# CY8C3246PVI_147 register map
File version: 0.1
CY8C32
Registers are 8-bit, read-write, no defined reset value unless marked. A register's access mark holds for its fields unless they carry their own. Offsets are from the block's base; lines under a group give offsets from that group; [hi:lo] are bit positions; {n}, {i} and the like mark numbered series; 'fields as' and 'values as' point back to an identical list; <NAME> marks a mode.

## Memory map
0x00000000 UART_RS485 — UART
0x00000000 ADC
0x00000000 MY_TIMER
0x00000000 COUNTER_ENC
0x00000000 WATCHDOG_COUNTER
0x00000000 PWM_MOTORS
0x00000000 PACER_TIMER
0x00006460 FF_STATUS
0x00006471 RESET_FF
0x00006472 RS485_CTS
0x00006473 FTDI_ENABLE_REG
0x00006474 WATCHDOG_REFRESH
0x00006477 WATCHDOG_ENABLER
0x00006478 MOTOR_ON_OFF
0x00006564 ADC_STATUS
0x00006574 POWER_ON_LED_REG
0x00006576 ADC_SOC
0x00006577 MOTOR_DIR
0x0000657B RESET_COUNTERS

## UART_RS485 — UART
Base 0x00000000
0x642B RX_UART_RS485_RX_ADDRESS1 — RX Address1 Register
0x643B RX_UART_RS485_RX_ADDRESS2 — RX Address2 Register
0x6443 TX_UART_RS485_TX_DATA — TX Data Register
0x644B RX_UART_RS485_RX_DATA — RX Data Register
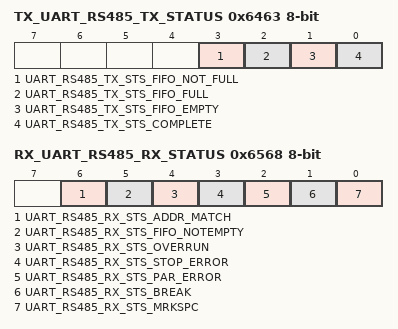
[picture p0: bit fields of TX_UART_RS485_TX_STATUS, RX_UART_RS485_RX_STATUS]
0x6463 TX_UART_RS485_TX_STATUS — TX status register
  [3] UART_RS485_TX_STS_FIFO_NOT_FULL ro, [2] UART_RS485_TX_STS_FIFO_FULL ro, [1] UART_RS485_TX_STS_FIFO_EMPTY ro, [0] UART_RS485_TX_STS_COMPLETE ro
0x6568 RX_UART_RS485_RX_STATUS — RX status register
  [6] UART_RS485_RX_STS_ADDR_MATCH ro, [5] UART_RS485_RX_STS_FIFO_NOTEMPTY ro, [4] UART_RS485_RX_STS_OVERRUN ro, [3] UART_RS485_RX_STS_STOP_ERROR ro, [2] UART_RS485_RX_STS_PAR_ERROR ro, [1] UART_RS485_RX_STS_BREAK ro, [0] UART_RS485_RX_STS_MRKSPC ro

## ADC_STATUS
Base 0x00006564
0x00 ADC_STATUS_STATUS_REG
0x20 ADC_STATUS_MASK_REG
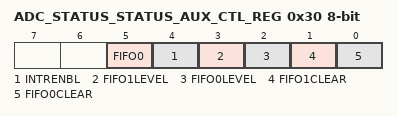
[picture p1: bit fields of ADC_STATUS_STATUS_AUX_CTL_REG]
0x30 ADC_STATUS_STATUS_AUX_CTL_REG
  [5] FIFO0 — FIFO0 clear
    1=ENABLED (Enable counter); 0=DISABLED (Disable counter)
  [4] INTRENBL — Enables or disables the Interrupt
    1=ENABLED (Interrupt enabled); 0=DISABLED (Interrupt disabled)
  [3] FIFO1LEVEL — FIFO level
    1=ENABLED (FIFO LVL: input mode: FIFO at least 1/2 empty; output mode: FIFO at least 1/2 full); 0=DISABLED (FIFO LVL: input mode: FIFO not full; output mode: FIFO not empty)
  [2] FIFO0LEVEL — FIFO level
    values as FIFO1LEVEL
  [1] FIFO1CLEAR — FIFO clear
    1=ENABLED (Clear FIFO state); 0=DISABLED (Normal FIFO operation)
  [0] FIFO0CLEAR — FIFO clear
    values as FIFO1CLEAR

## FF_STATUS
Base 0x00006460
Registers as ADC_STATUS (with ADC_STATUS read as FF_STATUS).

## MOTOR_ON_OFF
Base 0x00006478
0x00 MOTOR_ON_OFF_CONTROL_REG

## FTDI_ENABLE_REG
Base 0x00006473
Registers as MOTOR_ON_OFF (with MOTOR_ON_OFF read as FTDI_ENABLE_REG).

## RS485_CTS
Base 0x00006472
Registers as MOTOR_ON_OFF (with MOTOR_ON_OFF read as RS485_CTS).

## POWER_ON_LED_REG
Base 0x00006574
Registers as MOTOR_ON_OFF (with MOTOR_ON_OFF read as POWER_ON_LED_REG).

## ADC_SOC
Base 0x00006576
Registers as MOTOR_ON_OFF (with MOTOR_ON_OFF read as ADC_SOC).

## MOTOR_DIR
Base 0x00006577
Registers as MOTOR_ON_OFF (with MOTOR_ON_OFF read as MOTOR_DIR).

## RESET_COUNTERS
Base 0x0000657B
Registers as MOTOR_ON_OFF (with MOTOR_ON_OFF read as RESET_COUNTERS).

## WATCHDOG_ENABLER
Base 0x00006477
Registers as MOTOR_ON_OFF (with MOTOR_ON_OFF read as WATCHDOG_ENABLER).

## WATCHDOG_REFRESH
Base 0x00006474
Registers as MOTOR_ON_OFF (with MOTOR_ON_OFF read as WATCHDOG_REFRESH).

## RESET_FF
Base 0x00006471
Registers as MOTOR_ON_OFF (with MOTOR_ON_OFF read as RESET_FF).

## MY_TIMER
Base 0x00000000
0x43A3 MY_TIMER_GLOBAL_ENABLE — PM.ACT.CFG
  [3:0] en_timer — Enable timer/counters.
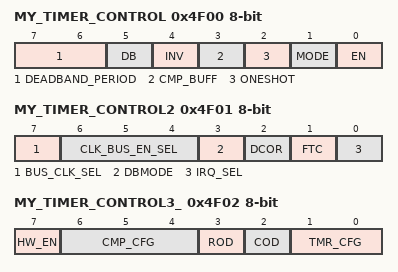
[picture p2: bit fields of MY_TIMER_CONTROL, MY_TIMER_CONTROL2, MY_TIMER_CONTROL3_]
0x4F00 MY_TIMER_CONTROL — TMRx.CFG0
  [7:6] DEADBAND_PERIOD
  [5] DB — Deadband mode--Deadband phases phi1 and phi2 are outputted on CMP and TC output pins respectively.
    0=Timer (CMP and TC are output.); 1=Deadband (PHI1 (instead of CMP) and PHI2 (instead of TC) are output.)
  [4] INV — Invert sense of TIMEREN signal
  [3] CMP_BUFF — Buffer compare register. Compare register updates only on timer terminal count.
  [2] ONESHOT — Timer stops upon reaching stop condition defined by TMR_CFG bits. Can be restarted by asserting TIMER RESET or disabling and re-enabling block.
  [1] MODE — Mode. (0 = Timer; 1 = Comparator)
    0=Timer mode. CNT/CMP register holds timer count value.; 1=Comparator mode. CNT/CMP register holds comparator threshold value.
  [0] EN — Enables timer/comparator.
0x4F01 MY_TIMER_CONTROL2 — TMRx.CFG1
  [7] BUS_CLK_SEL — Bus Clock selection.
  [6:4] CLK_BUS_EN_SEL — Digital Global Clock selection.
  [3] DBMODE — Deadband mode (asynchronous/synchronous). CMP output pin is also affected when not in deadband mode (CFG0.DEADBAND).
  [2] DCOR — Disable Clear on Read (DCOR) of Status Register SR0.
  [1] FTC — First Terminal Count (FTC). Setting this bit forces a single pulse on the TC pin when first enabled.
    0=Disable_FTC (Disable the single cycle pulse, which signifies the timer is starting.); 1=Enable_FTC (Enable the single cycle pulse, which signifies the timer is starting.)
  [0] IRQ_SEL — Irq selection. (0 = raw interrupts; 1 = status register interrupts)
0x4F02 MY_TIMER_CONTROL3_ — TMRx.CFG2
  [7] HW_EN — When set Timer Enable controls counting.
  [6:4] CMP_CFG — Comparator configurations
    0=Equal (Compare Equal); 1=Less_than (Compare Less Than); 2=Less_than_or_equal (Compare Less Than or Equal .); 3=Greater (Compare Greater Than .); 4=Greater_than_or_equal (Compare Greater Than or Equal)
  [3] ROD — Reset On Disable (ROD). Resets internal state of output logic
  [2] COD — Clear On Disable (COD). Clears or gates outputs to zero.
  [1:0] TMR_CFG — Timer configuration (MODE = 0): 000 = Continuous; 001 = Pulsewidth; 010 = Period; 011 = Stop on IRQ
    0=Continuous (Timer runs while EN bit of CFG0 register is set to '1'.); 1=Pulsewidth (Timer runs from positive to negative edge of TIMEREN.); 2=Period (Timer runs from positive to positive edge of TIMEREN.); 3=Irq (Timer runs until IRQ.)
0x4F04 MY_TIMER_PERIOD 16-bit — TMRx.PER0 - Assigned Period
0x4F06 MY_TIMER_COUNTER 16-bit — TMRx.CNT_CMP0 - Current Down Counter Value
